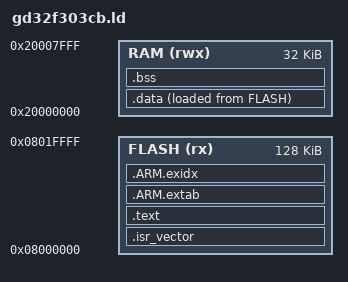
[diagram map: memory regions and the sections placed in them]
/* GD32F303CBT6: 128 KB flash @ 0x08000000, 32 KB SRAM @ 0x20000000 */
ENTRY(Reset_Handler)

MEMORY
{
  FLASH (rx)  : ORIGIN = 0x08000000, LENGTH = 128K
  RAM   (rwx) : ORIGIN = 0x20000000, LENGTH = 32K
}

_estack = ORIGIN(RAM) + LENGTH(RAM);

SECTIONS
{
  .isr_vector :
  {
    . = ALIGN(4);
    KEEP(*(.isr_vector))
    . = ALIGN(4);
  } > FLASH

  .text :
  {
    . = ALIGN(4);
    *(.text .text.*)
    *(.rodata .rodata.*)
    . = ALIGN(4);
    _etext = .;
  } > FLASH

  .ARM.extab :
  {
    *(.ARM.extab .ARM.extab.*)
  } > FLASH

  .ARM.exidx :
  {
    __exidx_start = .;
    *(.ARM.exidx .ARM.exidx.*)
    __exidx_end = .;
  } > FLASH

  _sidata = LOADADDR(.data);

  .data :
  {
    . = ALIGN(4);
    _sdata = .;
    *(.data .data.*)
    . = ALIGN(4);
    _edata = .;
  } > RAM AT > FLASH

  .bss (NOLOAD) :
  {
    . = ALIGN(4);
    _sbss = .;
    *(.bss .bss.*)
    *(COMMON)
    . = ALIGN(4);
    _ebss = .;
  } > RAM

  /DISCARD/ :
  {
    *(.note .note.*)
    *(.comment)
  }
}
